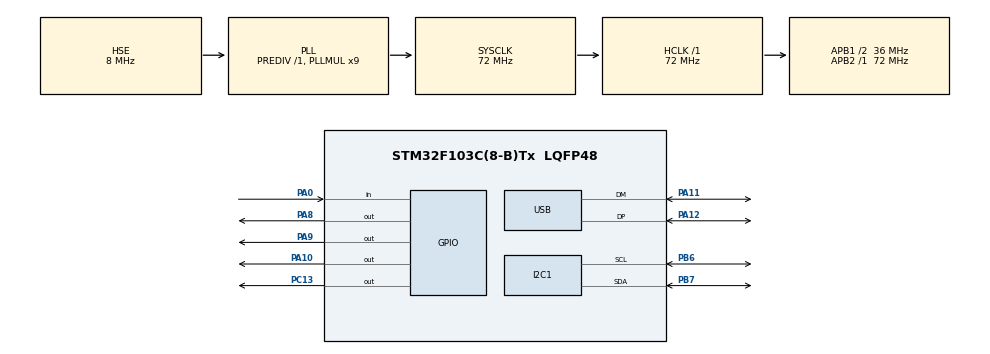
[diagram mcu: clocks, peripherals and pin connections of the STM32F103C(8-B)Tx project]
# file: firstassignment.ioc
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Mcu.Family=STM32F1
Mcu.Name=STM32F103C(8-B)Tx
Mcu.Package=LQFP48
NVIC.PriorityGroup=NVIC_PRIORITYGROUP_4
NVIC.TIM3_IRQn=true\:0\:0\:false\:false\:true\:true\:true\:true
PA0-WKUP.GPIO_PuPd=GPIO_PULLUP
PA0-WKUP.Signal=GPIO_Input
PA10.Signal=GPIO_Output
PA11.Mode=Device
PA11.Signal=USB_DM
PA12.Mode=Device
PA12.Signal=USB_DP
PA13.Mode=Serial_Wire
PA13.Signal=SYS_JTMS-SWDIO
PA14.Mode=Serial_Wire
PA14.Signal=SYS_JTCK-SWCLK
PA8.GPIO_ModeDefaultOutputPP=GPIO_MODE_OUTPUT_OD
PA8.GPIO_PuPd=GPIO_NOPULL
PA8.PinState=GPIO_PIN_SET
PA8.Signal=GPIO_Output
PA9.Signal=GPIO_Output
PB6.Mode=I2C
PB6.Signal=I2C1_SCL
PB7.Mode=I2C
PB7.Signal=I2C1_SDA
PC13-TAMPER-RTC.GPIO_ModeDefaultOutputPP=GPIO_MODE_OUTPUT_OD
PC13-TAMPER-RTC.GPIO_PuPd=GPIO_NOPULL
PC13-TAMPER-RTC.PinState=GPIO_PIN_SET
PC13-TAMPER-RTC.Signal=GPIO_Output
PD0-OSC_IN.Mode=HSE-External-Oscillator
PD0-OSC_IN.Signal=RCC_OSC_IN
PD1-OSC_OUT.Mode=HSE-External-Oscillator
PD1-OSC_OUT.Signal=RCC_OSC_OUT
ProjectManager.HeapSize=0x200
ProjectManager.StackSize=0x400
ProjectManager.TargetToolchain=MDK-ARM V5.32
RCC.AHBFreq_Value=72000000
RCC.APB1CLKDivider=RCC_HCLK_DIV2
RCC.APB1Freq_Value=36000000
RCC.APB1TimFreq_Value=72000000
RCC.APB2Freq_Value=72000000
RCC.APB2TimFreq_Value=72000000
RCC.HCLKFreq_Value=72000000
RCC.PLLMUL=RCC_PLL_MUL9
RCC.SYSCLKFreq_VALUE=72000000
RCC.SYSCLKSource=RCC_SYSCLKSOURCE_PLLCLK
RCC.USBFreq_Value=48000000
RCC.USBPrescaler=RCC_USBCLKSOURCE_PLL_DIV1_5
TIM3.Period=1439
TIM3.Prescaler=999
VP_TIM3_VS_ClockSourceINT.Mode=Internal
board=custom

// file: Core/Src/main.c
/* USER CODE BEGIN Header */
/**
  ******************************************************************************
  * @file           : main.c
  * @brief          : Main program body
  ******************************************************************************
  * @attention
  *
  * Copyright (c) 2026 STMicroelectronics.
  * All rights reserved.
  *
  * This software is licensed under terms that can be found in the LICENSE file
  * in the root directory of this software component.
  * If no LICENSE file comes with this software, it is provided AS-IS.
  *
  ******************************************************************************
  */
/* USER CODE END Header */
#include "main.h"
#include "i2c.h"
#include "tim.h"
#include "usb.h"
#include "gpio.h"

void SystemClock_Config(void);

int main(void)
{

  /* MCU Configuration--------------------------------------------------------*/

  /* Reset of all peripherals, Initializes the Flash interface and the Systick. */
  HAL_Init();

  /* Configure the system clock */
  SystemClock_Config();

  /* Initialize all configured peripherals */
  MX_GPIO_Init();
  MX_I2C1_Init();
  MX_USB_PCD_Init();
  MX_TIM3_Init();
  /* USER CODE BEGIN 2 */
	HAL_TIM_Base_Start_IT (&htim3 );
  /* USER CODE END 2 */

  /* Infinite loop */
  /* USER CODE BEGIN WHILE */
  while (1)//mission1
  {
		HAL_GPIO_WritePin(GPIOC ,GPIO_PIN_13, GPIO_PIN_RESET );
		HAL_GPIO_WritePin(GPIOA ,GPIO_PIN_9, GPIO_PIN_SET );

		HAL_Delay (249);

		HAL_GPIO_WritePin(GPIOC ,GPIO_PIN_13, GPIO_PIN_SET );
		HAL_GPIO_WritePin(GPIOA ,GPIO_PIN_9, GPIO_PIN_RESET );

		HAL_Delay (249);

    /* USER CODE END WHILE */

  }
}

void SystemClock_Config(void)
{
  RCC_OscInitTypeDef RCC_OscInitStruct = {0};
  RCC_ClkInitTypeDef RCC_ClkInitStruct = {0};
  RCC_PeriphCLKInitTypeDef PeriphClkInit = {0};

  /** Initializes the RCC Oscillators according to the specified parameters
  * in the RCC_OscInitTypeDef structure.
  */
  RCC_OscInitStruct.OscillatorType = RCC_OSCILLATORTYPE_HSE;
  RCC_OscInitStruct.HSEState = RCC_HSE_ON;
  RCC_OscInitStruct.HSEPredivValue = RCC_HSE_PREDIV_DIV1;
  RCC_OscInitStruct.HSIState = RCC_HSI_ON;
  RCC_OscInitStruct.PLL.PLLState = RCC_PLL_ON;
  RCC_OscInitStruct.PLL.PLLSource = RCC_PLLSOURCE_HSE;
  RCC_OscInitStruct.PLL.PLLMUL = RCC_PLL_MUL9;
  if (HAL_RCC_OscConfig(&RCC_OscInitStruct) != HAL_OK)
  {
    Error_Handler();
  }

  /** Initializes the CPU, AHB and APB buses clocks
  */
  RCC_ClkInitStruct.ClockType = RCC_CLOCKTYPE_HCLK|RCC_CLOCKTYPE_SYSCLK
                              |RCC_CLOCKTYPE_PCLK1|RCC_CLOCKTYPE_PCLK2;
  RCC_ClkInitStruct.SYSCLKSource = RCC_SYSCLKSOURCE_PLLCLK;
  RCC_ClkInitStruct.AHBCLKDivider = RCC_SYSCLK_DIV1;
  RCC_ClkInitStruct.APB1CLKDivider = RCC_HCLK_DIV2;
  RCC_ClkInitStruct.APB2CLKDivider = RCC_HCLK_DIV1;

  if (HAL_RCC_ClockConfig(&RCC_ClkInitStruct, FLASH_LATENCY_2) != HAL_OK)
  {
    Error_Handler();
  }
  PeriphClkInit.PeriphClockSelection = RCC_PERIPHCLK_USB;
  PeriphClkInit.UsbClockSelection = RCC_USBCLKSOURCE_PLL_DIV1_5;
  if (HAL_RCCEx_PeriphCLKConfig(&PeriphClkInit) != HAL_OK)
  {
    Error_Handler();
  }
}

/* USER CODE BEGIN 4 */

	/* void 	HAL_TIM_PeriodElapsedCallback(TIM_HandleTypeDef *htim)//mission2--mission3
	{
		if(htim == &htim3 )
		{
			//HAL_GPIO_TogglePin(GPIOA, GPIO_PIN_10 );
			static GPIO_PinState pre_status = GPIO_PIN_SET ;
			GPIO_PinState now_status = HAL_GPIO_ReadPin (GPIOA ,GPIO_PIN_0 );
			if(pre_status == GPIO_PIN_SET && now_status == GPIO_PIN_RESET)
			{
				HAL_GPIO_TogglePin(GPIOA,GPIO_PIN_8 );
			}
			pre_status = now_status ;
		}
	} */

	void HAL_GPIO_EXTI_Callback(uint16_t GPIO_Pin)//mission3
	{
		switch (GPIO_Pin )
		{
			case GPIO_PIN_0:
			{
				HAL_GPIO_TogglePin (GPIOA, GPIO_PIN_8 );
			}
			break;
			default:
			break ;
		}
	}

/* USER CODE END 4 */

void Error_Handler(void)
{
  __disable_irq();
  while (1)
  {
  }
}
